AUTOSAR XML (schema 3.1.2)
package /Components/SWC_DmpVlv_H
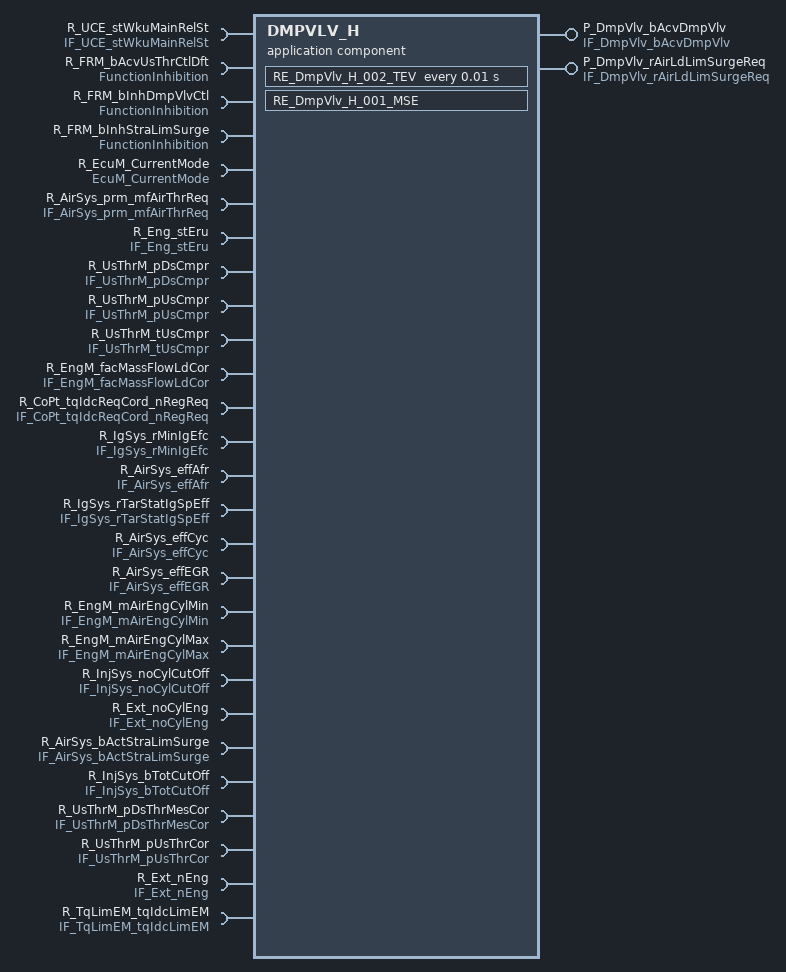
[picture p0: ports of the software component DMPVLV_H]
  application software component type DMPVLV_H  # DmpVlv_H
    4 x require port:
      R_UCE_stWkuMainRelSt: required-interface=IF_UCE_stWkuMainRelSt
      R_FRM_bAcvUsThrCtlDft: required-interface=FunctionInhibition
      R_FRM_bInhDmpVlvCtl: required-interface=FunctionInhibition
      R_FRM_bInhStraLimSurge: required-interface=FunctionInhibition
    provide port P_DmpVlv_bAcvDmpVlv: unqueued-sender-com-spec{data-element=DmpVlv_bAcvDmpVlv, can-invalidate=false, init-value=BooleanInitValue}, provided-interface=IF_DmpVlv_bAcvDmpVlv
    provide port P_DmpVlv_rAirLdLimSurgeReq: unqueued-sender-com-spec{data-element=DmpVlv_rAirLdLimSurgeReq, can-invalidate=false, init-value=UInt16InitValue}, provided-interface=IF_DmpVlv_rAirLdLimSurgeReq
    23 x require port:
      R_EcuM_CurrentMode: required-interface=EcuM_CurrentMode
      R_AirSys_prm_mfAirThrReq: unqueued-receiver-com-spec{data-element=AirSys_prm_mfAirThrReq, init-value=ArrayConstantValue, resync-time=0}, required-interface=IF_AirSys_prm_mfAirThrReq
      R_Eng_stEru: unqueued-receiver-com-spec{data-element=Eng_stEru, init-value=UInt8InitValue, resync-time=0}, required-interface=IF_Eng_stEru
      R_UsThrM_pDsCmpr: unqueued-receiver-com-spec{data-element=UsThrM_pDsCmpr, init-value=UInt16InitValue1, resync-time=0}, required-interface=IF_UsThrM_pDsCmpr
      R_UsThrM_pUsCmpr: unqueued-receiver-com-spec{data-element=UsThrM_pUsCmpr, init-value=UInt16InitValue3, resync-time=0}, required-interface=IF_UsThrM_pUsCmpr
      R_UsThrM_tUsCmpr: unqueued-receiver-com-spec{data-element=UsThrM_tUsCmpr, init-value=UInt16InitValue5, resync-time=0}, required-interface=IF_UsThrM_tUsCmpr
      R_EngM_facMassFlowLdCor: unqueued-receiver-com-spec{data-element=EngM_facMassFlowLdCor, init-value=UInt16InitValue7, resync-time=0}, required-interface=IF_EngM_facMassFlowLdCor
      R_CoPt_tqIdcReqCord_nRegReq: unqueued-receiver-com-spec{data-element=CoPt_tqIdcReqCord_nRegReq, init-value=SInt16InitValue, resync-time=0}, required-interface=IF_CoPt_tqIdcReqCord_nRegReq
      R_IgSys_rMinIgEfc: unqueued-receiver-com-spec{data-element=IgSys_rMinIgEfc, init-value=UInt16InitValue9, resync-time=0}, required-interface=IF_IgSys_rMinIgEfc
      R_AirSys_effAfr: unqueued-receiver-com-spec{data-element=AirSys_effAfr, init-value=UInt16InitValue11, resync-time=0}, required-interface=IF_AirSys_effAfr
      R_IgSys_rTarStatIgSpEff: unqueued-receiver-com-spec{data-element=IgSys_rTarStatIgSpEff, init-value=UInt16InitValue13, resync-time=0}, required-interface=IF_IgSys_rTarStatIgSpEff
      R_AirSys_effCyc: unqueued-receiver-com-spec{data-element=AirSys_effCyc, init-value=UInt16InitValue15, resync-time=0}, required-interface=IF_AirSys_effCyc
      R_AirSys_effEGR: unqueued-receiver-com-spec{data-element=AirSys_effEGR, init-value=UInt8InitValue17, resync-time=0}, required-interface=IF_AirSys_effEGR
      R_EngM_mAirEngCylMin: unqueued-receiver-com-spec{data-element=EngM_mAirEngCylMin, init-value=UInt32InitValue, resync-time=0}, required-interface=IF_EngM_mAirEngCylMin
      R_EngM_mAirEngCylMax: unqueued-receiver-com-spec{data-element=EngM_mAirEngCylMax, init-value=UInt32InitValue19, resync-time=0}, required-interface=IF_EngM_mAirEngCylMax
      R_InjSys_noCylCutOff: unqueued-receiver-com-spec{data-element=InjSys_noCylCutOff, init-value=UInt8InitValue21, resync-time=0}, required-interface=IF_InjSys_noCylCutOff
      R_Ext_noCylEng: unqueued-receiver-com-spec{data-element=Ext_noCylEng, init-value=UInt8InitValue23, resync-time=0}, required-interface=IF_Ext_noCylEng
      R_AirSys_bActStraLimSurge: unqueued-receiver-com-spec{data-element=AirSys_bActStraLimSurge, init-value=ConstantValue, resync-time=0}, required-interface=IF_AirSys_bActStraLimSurge
      R_InjSys_bTotCutOff: unqueued-receiver-com-spec{data-element=InjSys_bTotCutOff, init-value=BooleanInitValue25, resync-time=0}, required-interface=IF_InjSys_bTotCutOff
      R_UsThrM_pDsThrMesCor: unqueued-receiver-com-spec{data-element=UsThrM_pDsThrMesCor, init-value=UInt16InitValue27, resync-time=0}, required-interface=IF_UsThrM_pDsThrMesCor
      R_UsThrM_pUsThrCor: unqueued-receiver-com-spec{data-element=UsThrM_pUsThrCor, init-value=UInt16InitValue29, resync-time=0}, required-interface=IF_UsThrM_pUsThrCor
      R_Ext_nEng: unqueued-receiver-com-spec{data-element=Ext_nEng, init-value=ConstantValue31, resync-time=0}, required-interface=IF_Ext_nEng
      R_TqLimEM_tqIdcLimEM: unqueued-receiver-com-spec{data-element=TqLimEM_tqIdcLimEM, init-value=SInt16InitValue33, resync-time=0}, required-interface=IF_TqLimEM_tqIdcLimEM
  25 x constant specification:
    ArrayConstantValue
      value:
        array specification ArrayConstantValue: type=rt_Array_UInt16_2_m1
          integer literal Const: type=DT_AirSys_prm_mfAirThrReq, value=0
          integer literal Const1: type=DT_AirSys_prm_mfAirThrReq, value=0
    BooleanInitValue
      value:
        boolean literal BooleanInitValue: type=DT_DmpVlv_bAcvDmpVlv, value=false
    BooleanInitValue25
      value:
        boolean literal BooleanInitValue25: type=DT_InjSys_bTotCutOff, value=false
    ConstantValue
      value:
        boolean literal ConstantValue: type=DT_AirSys_bActStraLimSurge, value=false
    ConstantValue31
      value:
        integer literal ConstantValue31: type=DT_Ext_nEng, value=0
    InitValue_UInt16_0
      value:
        integer literal InitValue_UInt16_0: type=DT_DmpVlv_tiDmpVlvAcvTmr_irv, value=0
    SInt16InitValue
      value:
        integer literal SInt16InitValue: type=DT_CoPt_tqIdcReqCord_nRegReq, value=0
    SInt16InitValue33
      value:
        integer literal SInt16InitValue33: type=DT_TqLimEM_tqIdcLimEM, value=0
    UInt16InitValue
      value:
        integer literal UInt16InitValue: type=DT_DmpVlv_rAirLdLimSurgeReq, value=0
    UInt16InitValue1
      value:
        integer literal UInt16InitValue1: type=DT_UsThrM_pDsCmpr, value=0
    UInt16InitValue11
      value:
        integer literal UInt16InitValue11: type=DT_AirSys_effAfr, value=0
    UInt16InitValue13
      value:
        integer literal UInt16InitValue13: type=DT_IgSys_rTarStatIgSpEff, value=1024
    UInt16InitValue15
      value:
        integer literal UInt16InitValue15: type=DT_AirSys_effCyc, value=0
    UInt16InitValue27
      value:
        integer literal UInt16InitValue27: type=DT_UsThrM_pDsThrMesCor, value=0
    UInt16InitValue29
      value:
        integer literal UInt16InitValue29: type=DT_UsThrM_pUsThrCor, value=0
    UInt16InitValue3
      value:
        integer literal UInt16InitValue3: type=DT_UsThrM_pUsCmpr, value=0
    UInt16InitValue5
      value:
        integer literal UInt16InitValue5: type=DT_UsThrM_tUsCmpr, value=0
    UInt16InitValue7
      value:
        integer literal UInt16InitValue7: type=DT_EngM_facMassFlowLdCor, value=0
    UInt16InitValue9
      value:
        integer literal UInt16InitValue9: type=DT_IgSys_rMinIgEfc, value=0
    UInt32InitValue
      value:
        integer literal UInt32InitValue: type=DT_EngM_mAirEngCylMin, value=0
    UInt32InitValue19
      value:
        integer literal UInt32InitValue19: type=DT_EngM_mAirEngCylMax, value=0
    UInt8InitValue
      value:
        integer literal UInt8InitValue: type=DT_Eng_stEru, value=1
    UInt8InitValue17
      value:
        integer literal UInt8InitValue17: type=DT_AirSys_effEGR, value=0
    UInt8InitValue21
      value:
        integer literal UInt8InitValue21: type=DT_InjSys_noCylCutOff, value=0
    UInt8InitValue23
      value:
        integer literal UInt8InitValue23: type=DT_Ext_noCylEng, value=1
  internal behavior IB_DmpVlv_H: component=DMPVLV_H
    timing event EV_DmpVlv_H_002_TEV: start-on-event=RE_DmpVlv_H_002_TEV, period=0.01
    mode switch event EV_DmpVlv_H_001_MSE: start-on-event=RE_DmpVlv_H_001_MSE, activation=ENTRY, mode=R_EcuM_CurrentMode.currentMode.RUN
    inter runnable variable DmpVlv_tiDmpVlvAcvTmr_irv: sw-calibration-access=READ-WRITE, type=DT_DmpVlv_tiDmpVlvAcvTmr_irv, communication-approach=EXPLICIT, init-value=InitValue_UInt16_0
    runnable RE_DmpVlv_H_001_MSE: written-variable=DmpVlv_tiDmpVlvAcvTmr_irv
      data send point ds_DmpVlv_rAirLdLimSurgeReq: data-element=P_DmpVlv_rAirLdLimSurgeReq.DmpVlv_rAirLdLimSurgeReq
      data send point ds_DmpVlv_bAcvDmpVlv: data-element=P_DmpVlv_bAcvDmpVlv.DmpVlv_bAcvDmpVlv
    runnable RE_DmpVlv_H_002_TEV: read-variable=DmpVlv_tiDmpVlvAcvTmr_irv, written-variable=DmpVlv_tiDmpVlvAcvTmr_irv
      22 x data receive point:
        dr_AirSys_prm_mfAirThrReq: data-element=R_AirSys_prm_mfAirThrReq.AirSys_prm_mfAirThrReq
        dr_EngM_mAirEngCylMin: data-element=R_EngM_mAirEngCylMin.EngM_mAirEngCylMin
        dr_UsThrM_pDsThrMesCor: data-element=R_UsThrM_pDsThrMesCor.UsThrM_pDsThrMesCor
        dr_InjSys_noCylCutOff: data-element=R_InjSys_noCylCutOff.InjSys_noCylCutOff
        dr_Eng_stEru: data-element=R_Eng_stEru.Eng_stEru
        dr_EngM_facMassFlowLdCor: data-element=R_EngM_facMassFlowLdCor.EngM_facMassFlowLdCor
        dr_UsThrM_pDsCmpr: data-element=R_UsThrM_pDsCmpr.UsThrM_pDsCmpr
        dr_UsThrM_tUsCmpr: data-element=R_UsThrM_tUsCmpr.UsThrM_tUsCmpr
        dr_IgSys_rTarStatIgSpEff: data-element=R_IgSys_rTarStatIgSpEff.IgSys_rTarStatIgSpEff
        dr_Ext_nEng: data-element=R_Ext_nEng.Ext_nEng
        dr_UsThrM_pUsThrCor: data-element=R_UsThrM_pUsThrCor.UsThrM_pUsThrCor
        dr_InjSys_bTotCutOff: data-element=R_InjSys_bTotCutOff.InjSys_bTotCutOff
        dr_AirSys_effAfr: data-element=R_AirSys_effAfr.AirSys_effAfr
        dr_AirSys_effEGR: data-element=R_AirSys_effEGR.AirSys_effEGR
        dr_TqLimEM_tqIdcLimEM: data-element=R_TqLimEM_tqIdcLimEM.TqLimEM_tqIdcLimEM
        dr_AirSys_effCyc: data-element=R_AirSys_effCyc.AirSys_effCyc
        dr_IgSys_rMinIgEfc: data-element=R_IgSys_rMinIgEfc.IgSys_rMinIgEfc
        dr_Ext_noCylEng: data-element=R_Ext_noCylEng.Ext_noCylEng
        dr_UsThrM_pUsCmpr: data-element=R_UsThrM_pUsCmpr.UsThrM_pUsCmpr
        dr_AirSys_bActStraLimSurge: data-element=R_AirSys_bActStraLimSurge.AirSys_bActStraLimSurge
        dr_CoPt_tqIdcReqCord_nRegReq: data-element=R_CoPt_tqIdcReqCord_nRegReq.CoPt_tqIdcReqCord_nRegReq
        dr_EngM_mAirEngCylMax: data-element=R_EngM_mAirEngCylMax.EngM_mAirEngCylMax
      data send point ds_DmpVlv_rAirLdLimSurgeReq: data-element=P_DmpVlv_rAirLdLimSurgeReq.DmpVlv_rAirLdLimSurgeReq
      data send point ds_DmpVlv_bAcvDmpVlv: data-element=P_DmpVlv_bAcvDmpVlv.DmpVlv_bAcvDmpVlv
      sync call ssp_FRM_bInhDmpVlvCtl: operation=R_FRM_bInhDmpVlvCtl.GetFunctionPermission
      sync call ssp_FRM_bInhStraLimSurge: operation=R_FRM_bInhStraLimSurge.GetFunctionPermission
      sync call ssp_FRM_bAcvUsThrCtlDft: operation=R_FRM_bAcvUsThrCtlDft.GetFunctionPermission
  swc implementation Imp_DmpVlv_H: code-generator=Real-Time Workshop Embedded Coder 5.5 (R2010a) 25-Jan-2010, programming-language=C, behavior=IB_DmpVlv_H
    code-descriptors:
      code CodeDescriptor: type=SRC
        10 x xfile:
          DmpVlv_H_private_h: url=DmpVlv_H_private.h
          DmpVlv_H_Def_c: url=DmpVlv_H_Def.c
          DmpVlv_H_h: url=DmpVlv_H.h
          DmpVlv_H_c: url=DmpVlv_H.c
          DmpVlv_H_types_h: url=DmpVlv_H_types.h
          DmpVlv_H_MemMap_h: url=DmpVlv_H_MemMap.h
          DmpVlv_H_data_c: url=DmpVlv_H_data.c
          DmpVlv_H_Version_c: url=DmpVlv_H_Version.c
          DmpVlv_H_import_h: url=DmpVlv_H_import.h
          DmpVlv_H_Version_h: url=DmpVlv_H_Version.h
package /Components/SWC_DmpVlv_H/DmpVlv_H_IRVDatatypes
  integer type DT_DmpVlv_tiDmpVlvAcvTmr_irv: base-type=uint16, lower-limit=0, upper-limit=65535
